# nrf7140_ml register map
Vendor: Nordic Semiconductor; Series: nRF71; File version: 1
Registers are 32-bit, read-write, reset 0x0 unless marked. A register's access mark holds for its fields unless they carry their own. Offsets are from the block's base; [hi:lo] are bit positions; lines under a group give offsets from that group; {n}, {i} and the like mark numbered series; 'fields as' and 'values as' point back to an identical list.

## AXONS (part 1 of 2) — Axon wrapper
Base 0x4A004000
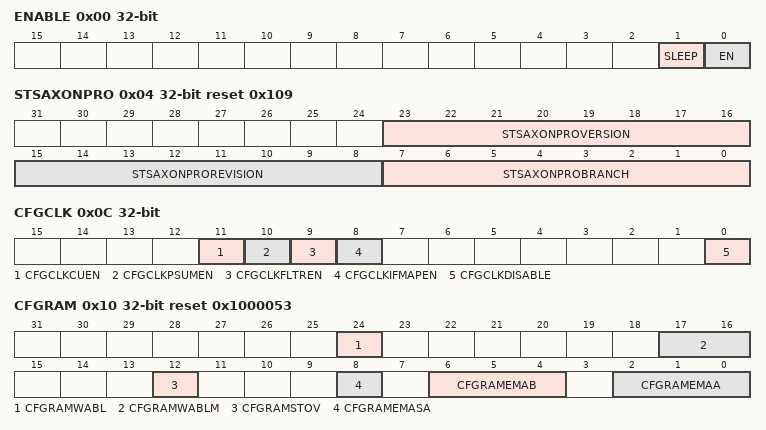
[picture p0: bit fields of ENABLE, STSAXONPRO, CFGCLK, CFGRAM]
0x00 ENABLE — Enable AXONS.
  [1] SLEEP — Enable sleep input of AXONS
    0=Disabled (AXONS sleep input not asserted.); 1=Enabled (AXONS sleep input asserted.)
  [0] EN — Enable
    0=Disabled (AXONS disabled (powered off).); 1=Enabled (AXONS enabled.)
0x800 AXONPRO group — Unspecified
  0x00 STSIP ro reset 0x2000 — ATLAZO Design ID
    [31:0] STSIPID — This is the ATLAZO IP number. It is 0x2000 to indicate Axon Pro. This can be used by FW driver to validate AXON pro location.
  0x04 STSAXONPRO ro reset 0x109 — Axon Pro Version ID
    [23:16] STSAXONPROVERSION — Axon Pro Version number. This can be used by FW driver to enable support multiple hardware versions.
    [15:8] STSAXONPROREVISION — Axon Pro Revision number
    [7:0] STSAXONPROBRANCH — Axon Pro Branch number
  0x08 CFGRESET — Soft Reset Register
    [0] CFGRESETSOFT — Active high soft reset. To perform reset, SW should write this bit to 1 then write it to 0. Doesn't reset programmable registers. Reset is performed asynchronously. Deassertion of reset is synchronized and only takes a few cycles to propagate through internal synchrnonizers
      0=NORMALOPERATION (Unspecified); 1=HOLDINRESET (Unspecified)
  0x0C CFGCLK — Clock Gating Register
    [11] CFGCLKCUEN — Active high clock enable for compute unit. Set to 0 to save power
      0=CLOCKGATEDWHENUNUSED (Unspecified); 1=CLOCKALWAYSENABLED (Unspecified)
    [10] CFGCLKPSUMEN — Active high clock enable for partial sum read DMA channel. Set to 0 to save power
      values as CFGCLKCUEN
    [9] CFGCLKFLTREN — Active high clock enable for filter read DMA channel. Set to 0 to save power
      values as CFGCLKCUEN
    [8] CFGCLKIFMAPEN — Active high clock enable for input feature map read DMA channel. Set to 0 to save power
      values as CFGCLKCUEN
    [0] CFGCLKDISABLE — Active high clock gating. Does not gate off clock to configuration registers to avoid lockup. This can be asserted when block is not in use to save power. This can also be used to measure leakage power in silicon with clocks disabled
      0=CLOCKENABLED (Unspecified); 1=CLOCKDISABLED (Unspecified)
  0x10 CFGRAM reset 0x1000053 — 22nm Ram Control Register
    [24] CFGRAMWABL — When logic 1, enable write assist for RAMs
    [17:16] CFGRAMWABLM — RAM write assist setting. 0 for 0.8V. 1 for 0.7,0.6V
    [12] CFGRAMSTOV — The RAM STOV feature allows you to override the self-timed generation of the clock pulse internal to the memory. When the STOV is asserted, the internal clock pulse is generated directly from the high phase of the external clock input.
    [8] CFGRAMEMASA — RAM EMASA enables the bitline keeper. Set EMASA to 1 to enable the bitline keeper. The memory provides a bitline keeper for Port A read operations. The keeper affects the cycle time in the read cycle. It does not affect the access time. Enabling the bitline keeper can help to counteract the effects of leakage in a high-leakage process environment.
    [6:4] CFGRAMEMAB — RAM port B pins slow down memory access and provide extra time for memory read and write operations. The access time, cycle time, and margin increase as the pins are driven from 000-111, respectively. That is, 000 is the fastest setting and 111 the slowest
    [2:0] CFGRAMEMAA — RAM port A pins slow down memory access and provide extra time for memory read and write operations. The access time, cycle time, and margin increase as the pins are driven from 000-111, respectively. That is, 000 is the fastest setting and 111 the slowest
  0x14 CFGDUMMY reset 0xC0FFEE — Dummy Register
    [31:0] CFGDUMMYVALUE — Doesn't have any associated behavior in block. Can be used by FW to test AHB slave port read and write operation
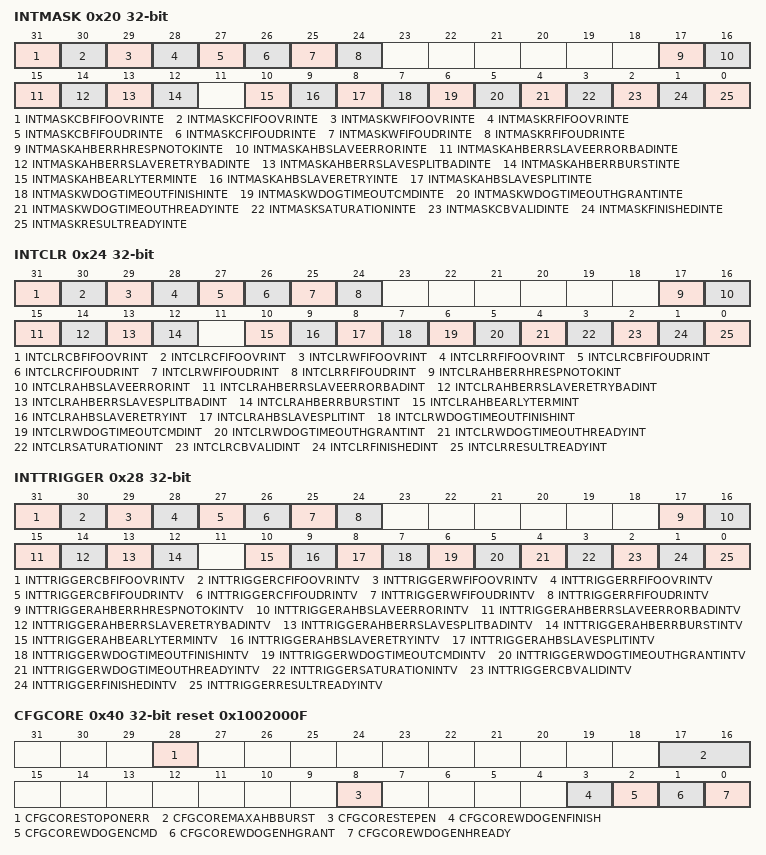
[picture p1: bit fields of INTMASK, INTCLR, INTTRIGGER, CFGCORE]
  0x20 INTMASK — Interrupt Mask Enable Register. A zero setting in any INTe bit prevents corresponding interrupt from propagating to processor.
    [all] fields
      0=INTERRUPTDISABLED (Unspecified); 1=INTERRUPTENABLED (Unspecified)
    [31] INTMASKCBFIFOOVRINTE — Enable generating Command Buffer Fifo Overun error interrupt
    [30] INTMASKCFIFOOVRINTE — Enable generating Control Fifo Overun error interrupt
    [29] INTMASKWFIFOOVRINTE — Enable generating Write data Fifo Overun error interrupt
    [28] INTMASKRFIFOOVRINTE — Enable generating Read data Fifo Overun error interrupt
    [27] INTMASKCBFIFOUDRINTE — Enable generating Command Buffer Fifo Underrun error interrupt
    [26] INTMASKCFIFOUDRINTE — Enable generating Control Fifo Underrun error interrupt
    [25] INTMASKWFIFOUDRINTE — Enable generating Write data Fifo Underrun error interrupt
    [24] INTMASKRFIFOUDRINTE — Enable generating Read data Fifo Underrun error interrupt
    [17] INTMASKAHBERRHRESPNOTOKINTE — Enable generating interrupt when following AHB behavior occurs. The slave did not follow the AHB protocol and responded with HRESP not being OKAY when expected
    [16] INTMASKAHBSLAVEERRORINTE — Enable generating interrupt when following AHB behavior occurs. The slave is indicating an error has occurred with the access
    [15] INTMASKAHBERRSLAVEERRORBADINTE — Enable generating interrupt when following AHB behavior occurs. The slave did not follow the AHB protocol when giving the HRESP ERROR
    [14] INTMASKAHBERRSLAVERETRYBADINTE — Enable generating interrupt when following AHB behavior occurs. The slave did not follow the AHB protocol when giving the HRESP RETRY
    [13] INTMASKAHBERRSLAVESPLITBADINTE — Enable generating interrupt when following AHB behavior occurs. The slave did not follow the AHB protocol when giving the HRESP SPLIT
    [12] INTMASKAHBERRBURSTINTE — Enable generating interrupt when following AHB behavior occurs. The master didn't provide the complete data for the entire burst
    [10] INTMASKAHBEARLYTERMINTE — Enable generating interrupt when AHB arbitor has terminated a burst early
    [9] INTMASKAHBSLAVERETRYINTE — Enable generating interrupt when AHB slave is telling the master to RETRY
    [8] INTMASKAHBSLAVESPLITINTE — Enable generating interrupt when AHB slave is telling the master to SPLIT
    [7] INTMASKWDOGTIMEOUTFINISHINTE — Enable generating interrupt when Axon Pro watchdog times out for processing all the command buffer
    [6] INTMASKWDOGTIMEOUTCMDINTE — Enable generating interrupt when Axon Pro watchdog times out for processing a single command
    [5] INTMASKWDOGTIMEOUTHGRANTINTE — Enable generating interrupt when Axon Pro watchdog times out for receiving hgrant on AHB master port
    [4] INTMASKWDOGTIMEOUTHREADYINTE — Enable generating interrupt when Axon Pro watchdog times out for receiving hready on AHB master port
    [3] INTMASKSATURATIONINTE — Enable generating interrupt when saturation occurs
    [2] INTMASKCBVALIDINTE — Enable generating interrupt when Axon Pro done processing valid portion of command buffer
    [1] INTMASKFINISHEDINTE — Enable generating interrupt when Axon Pro finished processing all command buffer
    [0] INTMASKRESULTREADYINTE — Enable generating interrupt when Axon Pro processed a single command and result is ready
  0x24 INTCLR — Interrupt and Clear Register. HW sets corresponding bit when interrupt event trigger occurs. FW writting any interrupt bit to 1 clears that bit.
    [all] fields
      0=NOEVENT (Unspecified); 1=EVENT (Unspecified)
    [31] INTCLRCBFIFOOVRINT — Command Buffer Fifo Overrun error Interrupt
    [30] INTCLRCFIFOOVRINT — Control Fifo Overrun error Interrupt
    [29] INTCLRWFIFOOVRINT — Write data Fifo Overrun error Interrupt
    [28] INTCLRRFIFOOVRINT — Read data Fifo Overrun error Interrupt
    [27] INTCLRCBFIFOUDRINT — Command Buffer Fifo Underrun error Interrupt
    [26] INTCLRCFIFOUDRINT — Control Fifo Underrun error Interrupt
    [25] INTCLRWFIFOUDRINT — Write Data Fifo Underrun error Interrupt
    [24] INTCLRRFIFOUDRINT — Read data Fifo Underrun error Interrupt
    [17] INTCLRAHBERRHRESPNOTOKINT — Interrupt event occures when the following AHB event occurs. The slave did not follow the AHB protocol and responded with HRESP not being OKAY when expected
    [16] INTCLRAHBSLAVEERRORINT — Interrupt event occures when the following AHB event occurs. The slave is indicating an error has occurred with the access
    [15] INTCLRAHBERRSLAVEERRORBADINT — Interrupt event occures when the following AHB event occurs. The slave did not follow the AHB protocol when giving the HRESP ERROR
    [14] INTCLRAHBERRSLAVERETRYBADINT — Interrupt event occures when the following AHB event occurs. The slave did not follow the AHB protocol when giving the HRESP RETRY
    [13] INTCLRAHBERRSLAVESPLITBADINT — Interrupt event occures when the following AHB event occurs. The slave did not follow the AHB protocol when giving the HRESP SPLIT
    [12] INTCLRAHBERRBURSTINT — Interrupt event occures when the following AHB event occurs. The master didn't provide the complete data for the entire burst
    [10] INTCLRAHBEARLYTERMINT — Interrupt event occures when the AHB arbitor has terminated a burst early
    [9] INTCLRAHBSLAVERETRYINT — Interrupt event occures when the AHB slave is telling the master to RETRY
    [8] INTCLRAHBSLAVESPLITINT — Interrupt event occures when the AHB slave is telling the master to SPLIT
    [7] INTCLRWDOGTIMEOUTFINISHINT — Interrupt event occures when all the command buffer is not processed within specified timeout limit. To recover from timeout condition, interrupt handler should 1. Disable watchdog 2. clear watchdog interrupt 3. Reset core 4. Renable watchdog
    [6] INTCLRWDOGTIMEOUTCMDINT — Interrupt event occures when a command is not processed within specified timeout limit. To recover from timeout condition, interrupt handler should 1. Disable watchdog 2. clear watchdog interrupt 3. Reset core 4. Renable watchdog
    [5] INTCLRWDOGTIMEOUTHGRANTINT — Interrupt event occures when the AHB master bus is not granted within specified timeout limit. To recover from timeout condition, interrupt handler should 1. Disable watchdog 2. clear watchdog interrupt 3. Reset core 4. Renable watchdog
    [4] INTCLRWDOGTIMEOUTHREADYINT — Interrupt event occures when AHB master bus is not ready within specified timeout limit. To recover from timeout condition, interrupt handler should 1. Disable watchdog 2. clear watchdog interrupt 3. Reset core 4. Renable watchdog
    [3] INTCLRSATURATIONINT — Interrupt event occurs when compute unit experiences saturation
    [2] INTCLRCBVALIDINT — Interrupt event occures when the Axon Pro done processing the valid portion of command buffer.
    [1] INTCLRFINISHEDINT — Interrupt event occures when the Axon Pro finishes processing all command buffer. FW needs to check all other error interrupts (result_ready_int is OK) are not asserted to determine that the command execution was successfull
    [0] INTCLRRESULTREADYINT — Interrupt event occures when the Axon Pro task is done processing one command. This is intended mainly for debug purposes
  0x28 INTTRIGGER ro — Interrupt Trigger Event. This register is not sticky and shows the trigger for the interrupt in corresponding int_clr register bit
    [31] INTTRIGGERCBFIFOOVRINTV — Command buffer Fifo Overrun error trigger
    [30] INTTRIGGERCFIFOOVRINTV — Control Fifo Overrun error trigger
    [29] INTTRIGGERWFIFOOVRINTV — Write data Fifo Overrun error trigger
    [28] INTTRIGGERRFIFOOVRINTV — Read data Fifo Overrun error trigger
    [27] INTTRIGGERCBFIFOUDRINTV — Command Buffer Fifo Underrun error trigger
    [26] INTTRIGGERCFIFOUDRINTV — Control Fifo Underrun error trigger
    [25] INTTRIGGERWFIFOUDRINTV — Write data Fifo Underrun error trigger
    [24] INTTRIGGERRFIFOUDRINTV — Read data Fifo Underrun error trigger
    [17] INTTRIGGERAHBERRHRESPNOTOKINTV — AHB Error HRESP not OK trigger
    [16] INTTRIGGERAHBSLAVEERRORINTV — AHB Slave Error trigger
    [15] INTTRIGGERAHBERRSLAVEERRORBADINTV — AHB error slave error bad trigger
    [14] INTTRIGGERAHBERRSLAVERETRYBADINTV — AHB error slave retry bad trigger
    [13] INTTRIGGERAHBERRSLAVESPLITBADINTV — AHB error slave split bad trigger
    [12] INTTRIGGERAHBERRBURSTINTV — AHB error burst trigger
    [10] INTTRIGGERAHBEARLYTERMINTV — AHB early termination trigger
    [9] INTTRIGGERAHBSLAVERETRYINTV — AHB slave retry trigger
    [8] INTTRIGGERAHBSLAVESPLITINTV — AHB slave split trigger
    [7] INTTRIGGERWDOGTIMEOUTFINISHINTV — Finished Watchdog timeout trigger
    [6] INTTRIGGERWDOGTIMEOUTCMDINTV — Command Watchdog timeout trigger
    [5] INTTRIGGERWDOGTIMEOUTHGRANTINTV — AHB master hgrant Watchdog timeout trigger
    [4] INTTRIGGERWDOGTIMEOUTHREADYINTV — AHB master hready Watchdog timeout trigger
    [3] INTTRIGGERSATURATIONINTV — Saturation trigger
    [2] INTTRIGGERCBVALIDINTV — Axon Pro done valid commad buffer trigger
    [1] INTTRIGGERFINISHEDINTV — Axon Pro Finished trigger
    [0] INTTRIGGERRESULTREADYINTV — Result ready trigger
  0x40 CFGCORE reset 0x1002000F — Configuration Register
    [28] CFGCORESTOPONERR — When 1, Axon Pro will stop when an error is detected for FW to perform a sw reset using cfg_reset_soft. When 0, Axon Pro statemachine will keep going when an error is detected
    [17:16] CFGCOREMAXAHBBURST — Specifies the maximum allowed burst size on the master AHB port
      0=SINGLE (Unspecified); 1=FOURBEATS (Unspecified); 2=EIGHTBEATS (Unspecified); 3=SIXTEENBEATS (Unspecified)
    [8] CFGCORESTEPEN — Set 1 to enable FW to step throught each command processed by triggering req_core_step. Set 0 so no FW involvement is needed per command
    [3] CFGCOREWDOGENFINISH — Set 1 to enable watchdog timer for processing all command buffer. Set 0 to disable watchdog timer
    [2] CFGCOREWDOGENCMD — Set 1 to enable watchdog timer for processing each command. Set 0 to disable watchdog timer
    [1] CFGCOREWDOGENHGRANT — Set 1 to enable watchdog timer for receiving hgrant on AHB master port. Set 0 to disable watchdog timer
    [0] CFGCOREWDOGENHREADY — Set 1 to enable watchdog timer for receiving hready on AHB master port. Set 0 to disable watchdog timer
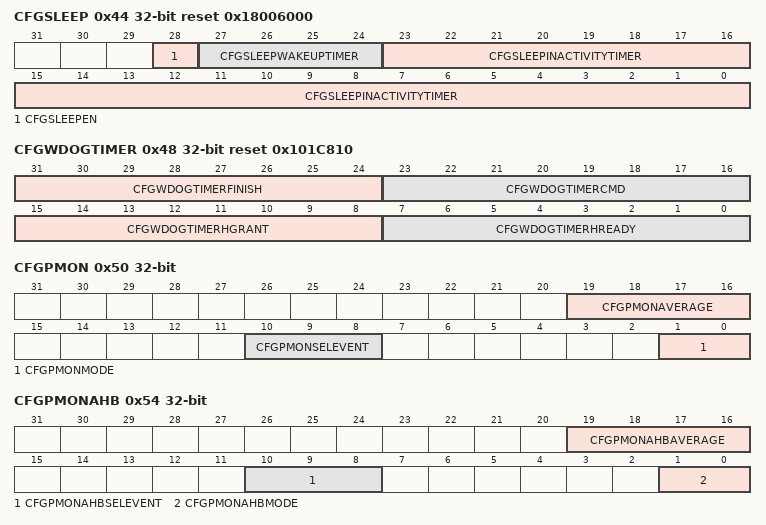
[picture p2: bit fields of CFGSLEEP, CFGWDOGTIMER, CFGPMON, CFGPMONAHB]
  0x44 CFGSLEEP reset 0x18006000 — Sleep Configuration Register
    [28] CFGSLEEPEN — When logic 1, The Axon Pro will sleep if there is no commands to process for the duraction of the time specified by cfg_sleep_inactivity_timer. The Axon Pro will automatically wakeup if any registers are written. Register reads will leave the Axon Pro in sleep. When logic 0, Axon Pro will not go into sleep mode
    [27:24] CFGSLEEPWAKEUPTIMER — Axon Pro will wait for the number of progammed cycles after wakeup to allow clock to settle
    [23:0] CFGSLEEPINACTIVITYTIMER — The number of clock cycles of inactivity to wait before going to sleep
  0x48 CFGWDOGTIMER reset 0x101C810 — Watchdog Configuration Register
    [31:24] CFGWDOGTIMERFINISH — Axon Pro will wait the programmed number of clock cyles * 2^28 for all the command buffer to finish processing, otherwise the watchdog timer will expire and trigger an interrupt
    [23:16] CFGWDOGTIMERCMD — Axon Pro will wait the programmed number of clock cyles * 2^16 for a command to finish processing, otherwise the watchdog timer will expire and trigger an interrupt
    [15:8] CFGWDOGTIMERHGRANT — Axon Pro will wait the programmed number of clock cyles to receive hgrant on AHB master port when requesting the bus, otherwise the watchdog timer will expire and trigger an interrupt
    [7:0] CFGWDOGTIMERHREADY — Axon Pro will wait the programmed number of clock cyles to receive hready on AHB master port, otherwise the watchdog timer will expire and trigger an interrupt
  0x4C CFGSPARE — Spare Register
    [31:0] CFGSPAREBIT — Spare bits, reserved for ECO. Should be set to all zero
  0x50 CFGPMON — Performance Monitor Configuration Register
    [19:16] CFGPMONAVERAGE — Amount of averaging in latency measurement mode. Value is 2 ^ cfg_pmon_average. 0 means no averaging. 1 means average two measurements. 2 means average 4 measurements. 3 means average 8 measurments, and so on
    [10:8] CFGPMONSELEVENT — In Free_Running mode, the first bit cfg_pmon_sel_event[0] = 1 means count the clock cycles only when AXON is active, 0 means keep counting. Otherwise cfg_pmon_sel_event selects which event to count or measure latency
      0=NUMINTERRUPTCYCLES (Unspecified); 1=NUMIDLECYCLES (Unspecified); 2=NUMBUSYCYCLES (Unspecified); 3=NUMFINISHEDINTERRUPTS (Unspecified); 4=NUMCOMMANDS (Unspecified); 5=NUMCONTROLBUFFERFETCHCYCLES (Unspecified); 6=NUMCOMMANDEXECUTECYCLES (Unspecified); 7=NUMFLUSHOUTPUTCYCLES (Unspecified)
    [1:0] CFGPMONMODE — Performance Monitor Mode of Operation. When disabled, sts_pmon_m/lsb_cnt is 0. When free running, sts_pmon_m/lsb_cnt is incrmenting 64 bit counter. The counter will rollover and no triggering is necessary. When counting events, the internal 64 bit counter will count the number of times the event specified by cfg_pmon_sel_event occurs. The counter will saturate when it reaches the maximum value. Once triggered by req_core_pmon_trig, sts_pmon_msb_cnt and sts_pmon_lsb_cnt will be updated with the internal counter value and the internal counter will be reset. When measuring latency, the internal 64 bit counter will start the latency measurment when triggered by req_core_pmon_trig. Once the measurement is complete, the value will be updated to sts_pmon_msb_cnt and sts_pmon_lsb_cnt and then req_core_pmon_trig will auto clear. The specific latency to measure is specifed by cfg_pmon_sel_event setting. The latency can be averaged over a number of measurments as specifed by cfg_pmon_average setting. The counter will saturate when maximum is reached
      0=DISABLED (Unspecified); 1=FREERUNNING (Unspecified); 2=EVENTCOUNT (Unspecified); 3=EVENTLATENCY (Unspecified)
  0x54 CFGPMONAHB — Performance Monitor AHB Configuration Register
    [19:16] CFGPMONAHBAVERAGE — Amount of averaging in latency measurement mode. Value is 2 ^ cfg_pmon_ahb_average. 0 means no averaging. 1 means average two measurements. 2 means average 4 measurements. 3 means average 8 measurments, and so on. After writing this bit, req_core_pmon_ahb_rw must be set 1 to take effect.
    [10:8] CFGPMONAHBSELEVENT — Select which event to count or measure latency. After writing this bit, req_core_pmon_ahb_rw must be set 1 to take effect.
      0=NUMWRITECYCLES (Unspecified); 1=NUMREADCYCLES (Unspecified); 2=NUMWRITEWAITCYCLES (Unspecified); 3=NUMREADWAITCYCLES (Unspecified); 4=NUMFIRSTREADWAITCYCLES (Unspecified); 5=NUMRESTREADWAITCYCLES (Unspecified); 6=NUMBUSCYCLES (Unspecified); 7=NUMBUSWAITCYCLES (Unspecified)
    [1:0] CFGPMONAHBMODE — Performance Monitor Mode of Operation. After writing this bit, req_core_pmon_ahb_rw must be set 1 to take effect. When disabled, sts_pmon_ahb_m/lsb_cnt is 0. When free running, sts_pmon_ahb_m/lsb_cnt is incrmenting 64 bit counter. The counter will rollover and no triggering is necessary. When counting events, the internal 64 bit counter will count the number of times the event specified by cfg_pmon_ahb_sel_event occurs. The counter will saturate when it reaches the maximum value. Once triggered by req_core_pmon_ahb_trig, sts_pmon_ahb_msb_cnt and sts_pmon_ahb_lsb_cnt will be updated with the internal counter value and the internal counter will be reset. When measuring latency, the internal 64 bit counter will start the latency measurment when triggered by req_core_pmon_ahb_trig. Once the measurement is complete, the value will be updated to sts_pmon_ahb_msb_cnt and sts_pmon_ahb_lsb_cnt and then req_core_pmon_ahb_trig will auto clear. The specific latency to measure is specifed by cfg_pmon_ahb_sel_event setting. The latency can be averaged over a number of measurments as specifed by cfg_pmon_ahb_average setting. The counter will saturate when maximum is reached
  0x7C CFGPSUMCONFIG2 — Partial Sum Configuration Register
    [15:0] CFGPSUMCONFIG2ZSTRIDE — Offset value in byte between two partial sums.
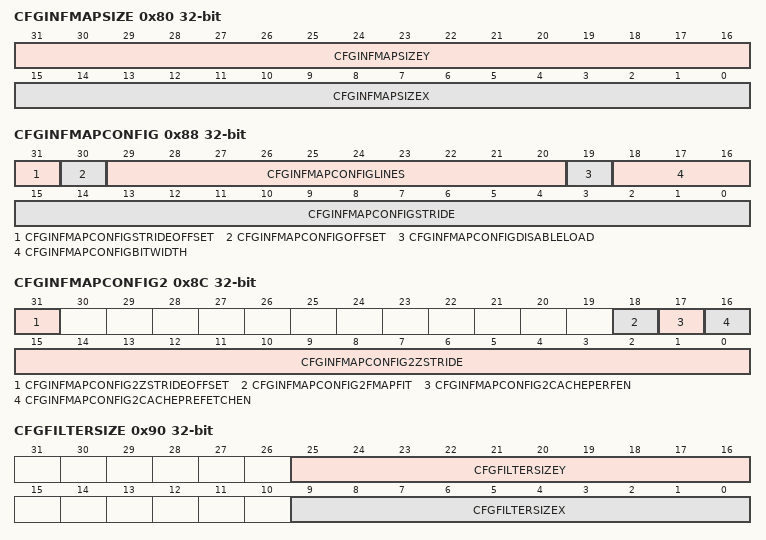
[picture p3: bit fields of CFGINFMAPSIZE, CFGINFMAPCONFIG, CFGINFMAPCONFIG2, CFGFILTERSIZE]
  0x80 CFGINFMAPSIZE — Input Feature Map Size Register
    [31:16] CFGINFMAPSIZEY — Input feature map number of rows. Units in pixels (8 bit or 4 bits)
    [15:0] CFGINFMAPSIZEX — Input feature map number of columns. Units in pixels
  0x84 CFGINFMAPPTR — Input Feature Map Pointer
    [31:0] CFGINFMAPPTRADDR — Byte address of input feature map.
  0x88 CFGINFMAPCONFIG — Input Feature Map Configuration Register
    [31] CFGINFMAPCONFIGSTRIDEOFFSET — When logic 1, addes a nibble offset to stride
    [30] CFGINFMAPCONFIGOFFSET — When logic 1, starts at upper nibble of indicated byte address in 4 bit mode. When logic 0, starts at lower nibble of indicated byte address. Must be set to 0 if bit width is larger than 4 bits.
    [29:20] CFGINFMAPCONFIGLINES — Indicates the number of lines to prefetch and use in internal line buffer storage.
    [19] CFGINFMAPCONFIGDISABLELOAD — When logic 1, AXON pro will not load input feature map from memory, instead it will reuse the previous data stored in the line buffer.
    [18:16] CFGINFMAPCONFIGBITWIDTH — Bit width of input feature map pixels. For feature map only 4 and 8 bits are supported.
      2=BITS04 (Unspecified); 3=BITS08 (Unspecified); 4=BITS16 (Unspecified); 5=BITS32 (Unspecified)
    [15:0] CFGINFMAPCONFIGSTRIDE — Offset value to required stripe of input feature map. Units in bytes. Minimum allowed value is equal to number of bytes in the columns width.
  0x8C CFGINFMAPCONFIG2 — Input Feature Map Configuration Register 2
    [31] CFGINFMAPCONFIG2ZSTRIDEOFFSET — Additional nibble offset to be added to z_stride. Used in pointwise convolution command. Should be set to0 if bit width is not 4 bit setting.
    [18] CFGINFMAPCONFIG2FMAPFIT — 1: indiacates that all fmap data fits in multi fiter modes, used for PWC and CONV only
    [17] CFGINFMAPCONFIG2CACHEPERFEN — enable fmap cache performance mode
    [16] CFGINFMAPCONFIG2CACHEPREFETCHEN — enable fmap cache prefetch mode
    [15:0] CFGINFMAPCONFIG2ZSTRIDE — Offset value in byte between two feature map surfaces.
  0x90 CFGFILTERSIZE — Filter Size Register
    [25:16] CFGFILTERSIZEY — Filter number of rows. Units in pixels
    [9:0] CFGFILTERSIZEX — Filter number of columns. Units in pixels
  0x94 CFGFILTERPTR — Filter Pointer
    [31:0] CFGFILTERPTRADDR — Byte address of filter. Must be 32 bit aligned
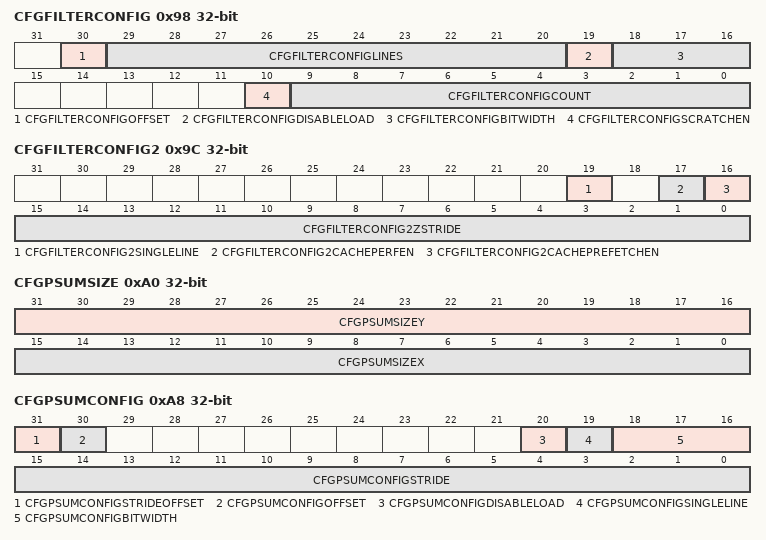
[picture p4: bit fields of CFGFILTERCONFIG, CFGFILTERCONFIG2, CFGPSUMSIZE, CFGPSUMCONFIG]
  0x98 CFGFILTERCONFIG — Filter Configuration Register
    [30] CFGFILTERCONFIGOFFSET — When logic 1, starts at upper nibble of indicated byte address in 4 bit mode. When logic 0, starts at lower nibble of indicated byte address. Must be set to 0 if bit width is larger than 4 bits.
    [29:20] CFGFILTERCONFIGLINES — Indicates the number of lines to prefetch and use in internal line buffer storage.
    [19] CFGFILTERCONFIGDISABLELOAD — When logic 1, AXON pro will not load input feature map from memory, instead it will reuse the previous data stored in the line buffer.
    [18:16] CFGFILTERCONFIGBITWIDTH — Bit width of filter pixels. For filters, only 4 bits and 8 bits supported.
      values as AXONPRO.CFGINFMAPCONFIG.CFGINFMAPCONFIGBITWIDTH
    [10] CFGFILTERCONFIGSCRATCHEN — When logic 1, filter data is stored in scratch flops to save power. This mode is limited to filters sizes upto 5x5. When logic 0, filter data is stored in internal line buffer RAM
    [9:0] CFGFILTERCONFIGCOUNT — Number of filters to apply to given input feature map
  0x9C CFGFILTERCONFIG2 — Filter Configuration Register 2
    [19] CFGFILTERCONFIG2SINGLELINE — When logic 1, all the filters are fetched using a single transaction for maximizing bus utilization. When logic 0, each filter row is fetched independantly.
    [17] CFGFILTERCONFIG2CACHEPERFEN — enable filter cache performance mode
    [16] CFGFILTERCONFIG2CACHEPREFETCHEN — enable filter cache prefetch mode
    [15:0] CFGFILTERCONFIG2ZSTRIDE — Offset value in byte between two filters surfaces. used on conv and pwc.
  0xA0 CFGPSUMSIZE — Partial Sum Size Register
    [31:16] CFGPSUMSIZEY — Partial sum number of rows. Units in pixels
    [15:0] CFGPSUMSIZEX — Partial sum number of columns. Units in rows
  0xA4 CFGPSUMPTR — Partial Sum Pointer
    [31:0] CFGPSUMPTRADDR — Byte address of partial sum. Must be 32 bit aligned
  0xA8 CFGPSUMCONFIG — Partial Sum Configuration Register
    [31] CFGPSUMCONFIGSTRIDEOFFSET — When logic 1, addes a nibble offset to stride
    [30] CFGPSUMCONFIGOFFSET — When logic 1, starts at upper nibble of indicated byte address in 4 bit mode. When logic 0, starts at lower nibble of indicated byte address. Must be set to 0 if bit width is larger than 4 bits.
    [20] CFGPSUMCONFIGDISABLELOAD — When logic 1, AXON pro will not load partial sum from memory, instead it will reuse the previous data stored in the partial sum buffer. When logic 0, AXON pro will load partial sum from memory.
    [19] CFGPSUMCONFIGSINGLELINE — When logic 1, output partial sum as a single line.
    [18:16] CFGPSUMCONFIGBITWIDTH — Bit width of partial sum pixels
      values as AXONPRO.CFGINFMAPCONFIG.CFGINFMAPCONFIGBITWIDTH
    [15:0] CFGPSUMCONFIGSTRIDE — Offset value to required stripe of partial sum. Units in bytes. Must be 32 bit aligned
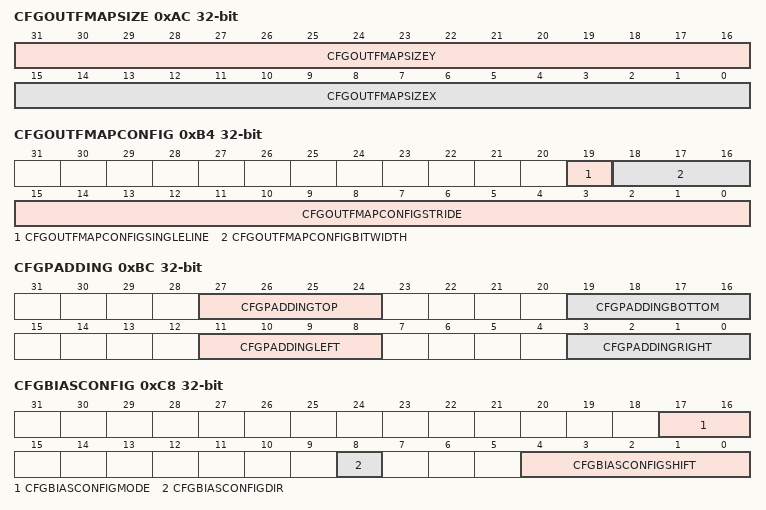
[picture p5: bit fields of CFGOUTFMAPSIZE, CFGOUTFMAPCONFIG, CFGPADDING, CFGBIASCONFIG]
  0xAC CFGOUTFMAPSIZE — Output Feature Map Size Register
    [31:16] CFGOUTFMAPSIZEY — Output feature map number of rows. Units in pixels
    [15:0] CFGOUTFMAPSIZEX — Output feature map number of columns. Units in pixels
  0xB0 CFGOUTFMAPPTR — Output Feature Map Pointer
    [31:0] CFGOUTFMAPPTRADDR — Byte address of output feature map. Must be 32 bit aligned
  0xB4 CFGOUTFMAPCONFIG — Output Feature Map Configuration Register
    [19] CFGOUTFMAPCONFIGSINGLELINE — When logic 1, output feature map as a single line
    [18:16] CFGOUTFMAPCONFIGBITWIDTH — Bit width of output feature map pixels. Only 8, 16 and 32 bits supported.
      values as AXONPRO.CFGINFMAPCONFIG.CFGINFMAPCONFIGBITWIDTH
    [15:0] CFGOUTFMAPCONFIGSTRIDE — Offset value to required stripe of output feature map. Units in bytes. Must be 32 bit aligned
  0xB8 CFGOUTFMAPCONFIG2 — Output Feature Map Config2
    [15:0] CFGOUTFMAPCONFIG2ZSTRIDE — Offset value in byte between two output feature map surfaces.
  0xBC CFGPADDING — Padding Control Register
    [27:24] CFGPADDINGTOP — Number of pixel rows to pad at top of input activation map. Units are in pixels
    [19:16] CFGPADDINGBOTTOM — Number of pixel rows to pad at bottom of input activation map. Units are in pixels
    [11:8] CFGPADDINGLEFT — Number of pixel columns to pad at left of input activation map. Units are in pixels
    [3:0] CFGPADDINGRIGHT — Number of pixel columns to pad at right of input activation map. Units are in pixels
  0xC0 CFGPADDINGCONFIG — Padding Config
    [15:0] CFGPADDINGVALUE — 16 bit signed value for padding.
  0xC4 CFGBIAS — Bias Register
    [31:0] CFGBIASVALUE — Bias value to add to output
  0xC8 CFGBIASCONFIG — Bias Configuration Register
    [17:16] CFGBIASCONFIGMODE — Where in computation pipeline to add the bias
    [8] CFGBIASCONFIGDIR — Shift direction for bias value
      0=SHIFTRIGHT (Unspecified); 1=SHIFTLEFT (Unspecified)
    [4:0] CFGBIASCONFIGSHIFT — Bias shift amount
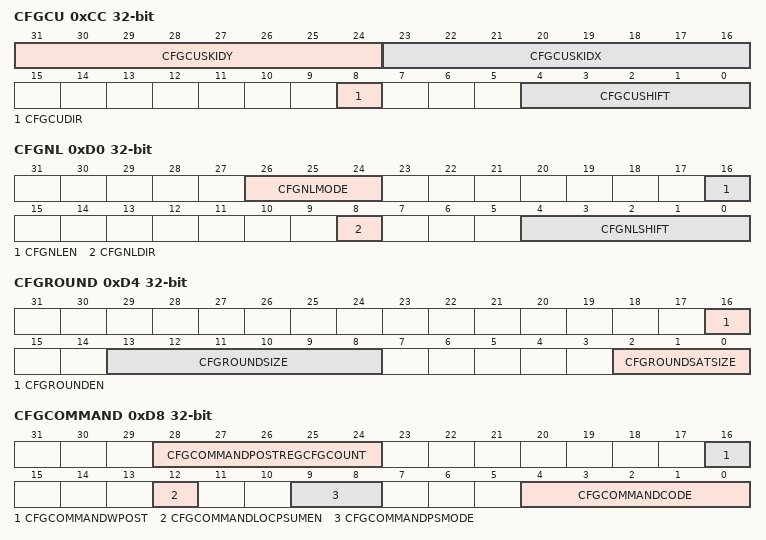
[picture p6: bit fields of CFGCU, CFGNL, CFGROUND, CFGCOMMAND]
  0xCC CFGCU — Compute Unit Configuration Register
    [31:24] CFGCUSKIDY — Number of pixel rows to move filter during convolution. Units in pixels
    [23:16] CFGCUSKIDX — Number of pixel columns to move filter during convolution. Units in pixels
    [8] CFGCUDIR — Shift direction for compute unit output
      0=SHIFTRIGHT (Unspecified); 1=SHIFTLEFT (Unspecified)
    [4:0] CFGCUSHIFT — Shift amount for compute unit output
  0xD0 CFGNL — Non Linear Configuration Register
    [26:24] CFGNLMODE — Non linear mode
      0=RELUHW (Unspecified); 1=LOOKUPTABLE16BITLSB (Unspecified); 2=LOOKUPTABLE16BITMSB (Unspecified); 3=LOOKUPTABLE32BIT (Unspecified); 5=RELULOOKUPTABLE16BITLSB (Unspecified); 6=RELULOOKUPTABLE16BITMSB (Unspecified); 7=RELULOOKUPTABLE32BIT (Unspecified)
    [16] CFGNLEN — Enable non linear
    [8] CFGNLDIR — Shift direction after non linear processing
      0=SHIFTRIGHT (Unspecified); 1=SHIFTLEFT (Unspecified)
    [4:0] CFGNLSHIFT — Shift amount after non linear processing
  0xD4 CFGROUND — Rounding and Saturation Configuration Register
    [16] CFGROUNDEN — Enable rounding
    [13:8] CFGROUNDSIZE — Rounding size
    [2:0] CFGROUNDSATSIZE — Saturation size
      values as AXONPRO.CFGINFMAPCONFIG.CFGINFMAPCONFIGBITWIDTH
  0xD8 CFGCOMMAND — Command Configurtion Register
    [28:24] CFGCOMMANDPOSTREGCFGCOUNT — number of registers that can be configured after each command. this register is only applicable to PWC and CONV with number of filters are larger than 1
    [16] CFGCOMMANDWPOST — When logic 1, writes are posted. When logic 0, writes are flushed. This should be set only if current command doesnot need output of previous command as it may still be infligt
    [12] CFGCOMMANDLOCPSUMEN — When logic 1, enable PSUM local TCM access. Setting this bit to 0 will disable access for PSUM. TCM will be used to store/read PSUM data
    [9:8] CFGCOMMANDPSMODE — Partial Sum input, output mode
      0=PARTIALNONE (Unspecified); 1=PARTIALOUT (Unspecified); 2=PARTIALIN (Unspecified); 3=PARTIALINOUT (Unspecified)
    [4:0] CFGCOMMANDCODE — Command to execute
      0=DMA (Unspecified); 1=CONV (Unspecified); 2=PWCONV (Unspecified); 3=MAXPOOL (Unspecified); 4=AVGPOOL (Unspecified); 5=MATMUL (Unspecified); 6=AXPBY (Unspecified); 7=AXPB (Unspecified); 8=XTY (Unspecified); 9=XPY (Unspecified)
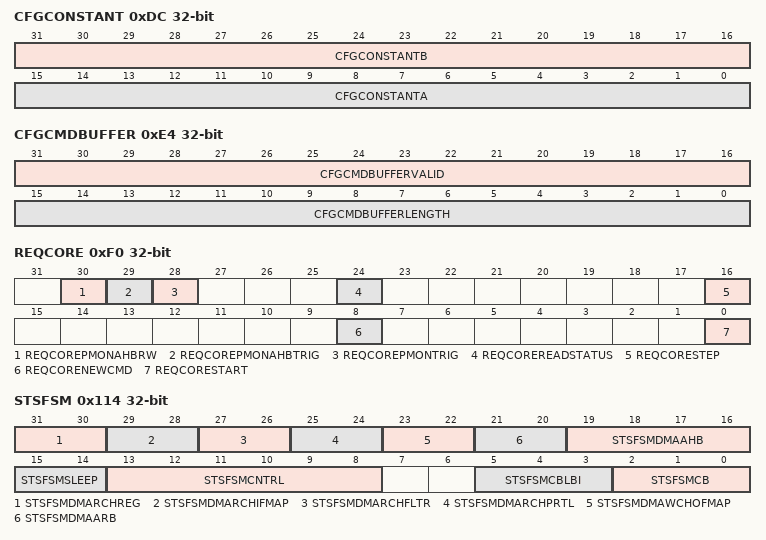
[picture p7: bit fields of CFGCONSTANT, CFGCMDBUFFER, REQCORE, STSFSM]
  0xDC CFGCONSTANT — Constant Configuration Register
    [31:16] CFGCONSTANTB — A constant value. two's complement format
    [15:0] CFGCONSTANTA — B constant value. two's complement format
  0xE0 CFGCMDBUFFERPTR — Command Buffer Pointer
    [31:0] CFGCMDBUFFERPTRADDR — Byte address of command buffer. Must be aligned to 32 bit
  0xE4 CFGCMDBUFFER — Command Buffer Configuration Register
    [31:16] CFGCMDBUFFERVALID — Number of valid DWORDS (32 bits) in command buffer. FW updates this field to synchronize with HW and let HW progress upto this location. Each Entry is atleast 64 bitss. Entry[15:0] = address. Entry[19:16] = active low write byte enable, 0 = write all 4 bytes, E=write only first byte. Entry[31:24] = number of data DWORDS. Entry[63:32] = data0, .... Little endian format, ie Entry[31:0] is lower address than Entry[63:32]
    [15:0] CFGCMDBUFFERLENGTH — Total number of DWORDS in command buffer.
  0xF0 REQCORE — Core Request Register
    [30] REQCOREPMONAHBRW — Update cfg_pmon_ahb_mode, cfg_pmon_ahb_sel_event, cfg_pmon_ahb_average settings to core.
    [29] REQCOREPMONAHBTRIG — Update sts_pmon_ahb_msb_cnt and sts_pmon_ahb_lsb_cnt. Not required in free running mode.
    [28] REQCOREPMONTRIG — Update sts_pmon_msb_cnt and sts_pmon_lsb_cnt. Not required in free running mode.
    [24] REQCOREREADSTATUS — Sample all status bits that are in the ahb clock domiain
    [16] REQCORESTEP — Proceed to executing the next command
    [8] REQCORENEWCMD — Execute new command
    [0] REQCORESTART — Start processing the command buffer
  0x100 STSCMDBUFFERPTR ro — Command Buffer Pointer Status
    [31:0] STSCMDBUFFERPTRADDR — Read back of the next byte address of commnd buffer pointer to execute. Similar to program counter in traditional processor.
  0x104 STSASLEEP ro — Sleep Status Register
    [0] STSASLEEPMODE — When logic 1, indicates Axon Pro is in sleep state. Any register write will wakeup Axon Pro
      0=NORMALMODE (Unspecified); 1=SLEEPMODE (Unspecified)
  0x108 STSMSBACC ro — Accumulator Most Significant Status Register
    [31:0] STSMSBACCRESULT — Accumulator[63:32]
  0x10C STSLSBACC ro — Accumulator Least Significant Status Register
    [31:0] STSLSBACCRESULT — Accumulator[31:0]
  0x110 STSMAHB ro — AHB Master Last Access Address Status Register
    [31:0] STSMAHBADDR — The address of the last access preformed by AHB master. Must trigger req_core_read_status to update this field
  0x114 STSFSM ro — Finite State Machines Status Register
    [31:30] STSFSMDMARCHREG — State of DMA Registers Read Channel statemachine
      0=STATEIDLE (Unspecified); 1=STATEREADREQ (Unspecified); 2=STATEREADDATA (Unspecified); 3=STATEERR (Unspecified)
    [29:28] STSFSMDMARCHIFMAP — State of DMA Input Feature Map Read Channel statemachine
      values as STSFSMDMARCHREG
    [27:26] STSFSMDMARCHFLTR — State of DMA Filter Read Channel statemachine
      values as STSFSMDMARCHREG
    [25:24] STSFSMDMARCHPRTL — State of DMA Partials Read Channel statemachine
      values as STSFSMDMARCHREG
    [23:22] STSFSMDMAWCHOFMAP — State of DMA Output Feature Map Write Channel statemachine
      0=STATEIDLE (Unspecified); 1=STATEWRITEREQ (Unspecified); 2=STATEWRITEDATA (Unspecified); 3=STATEERR (Unspecified)
    [21:20] STSFSMDMAARB — State of DMA Arbitor statemachine
      0=STATEIDLE (Unspecified); 1=STATEWRITE (Unspecified); 2=STATEREAD (Unspecified); 3=STATEERR (Unspecified)
    [19:16] STSFSMDMAAHB — State of DMA AHB interface statemachine. Must trigger req_core_read_status to update this field
      0=STATEIDLE (Unspecified); 1=STATEREQ (Unspecified); 2=STATEWRITE (Unspecified); 3=STATEREAD (Unspecified); 4=STATESWRITE (Unspecified); 5=STATESWRITEREQ (Unspecified); 6=STATESREAD (Unspecified); 7=STATESREADREQ (Unspecified); 8=STATEERR (Unspecified)
    [15:14] STSFSMSLEEP — State of sleep statemachine
      0=STATEACTIVE (Unspecified); 1=STATEINACTIVE (Unspecified); 2=STATESLEEP (Unspecified); 3=STATEWAKEUP (Unspecified)
    [13:8] STSFSMCNTRL — State of controller state machine
    [5:3] STSFSMCBLBI — State of command buffer LBI state machine
      0=STATEIDLE (Unspecified); 1=STATEADDR (Unspecified); 2=STATEDATA (Unspecified); 3=STATEWAITCMD (Unspecified); 4=STATEWAITSTEP (Unspecified)
    [2:0] STSFSMCB — State of command buffer state machine
      0=STATEIDLE (Unspecified); 1=STATESTART (Unspecified); 2=STATEREADREQ (Unspecified); 3=STATEREADDATA (Unspecified); 4=STATEWAIT (Unspecified); 5=STATEERR (Unspecified)
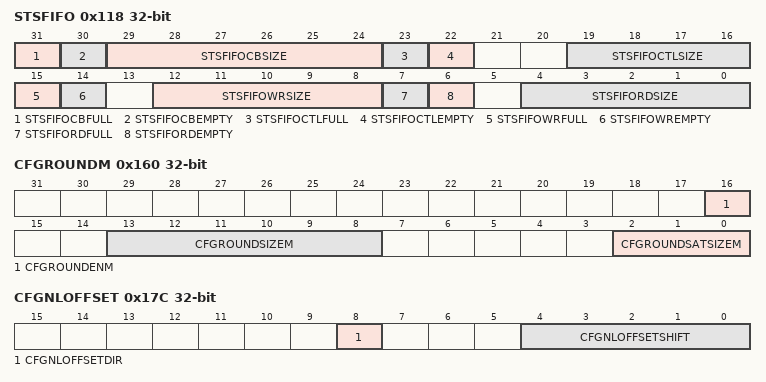
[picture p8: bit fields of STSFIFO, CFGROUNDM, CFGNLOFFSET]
  0x118 STSFIFO ro — FIFO Level Status Register
    [31] STSFIFOCBFULL — Command Buffer Fifo Full indicator
    [30] STSFIFOCBEMPTY — Command Buffer Fifo Empty indicator
    [29:24] STSFIFOCBSIZE — Number of entries used in Command Buffer Fifo
    [23] STSFIFOCTLFULL — Control Fifo Full indicator
    [22] STSFIFOCTLEMPTY — Control Fifo Empty indicator. Must trigger req_core_read_status to update this field
    [19:16] STSFIFOCTLSIZE — Number of entries used in Control Fifo
    [15] STSFIFOWRFULL — Write data Fifo Full indicator
    [14] STSFIFOWREMPTY — Write data Fifo Empty indicator. Must trigger req_core_read_status to update this field
    [12:8] STSFIFOWRSIZE — Number of entries used in Write data Fifo
    [7] STSFIFORDFULL — Read data Fifo Full indicator. Must trigger req_core_read_status to update this field
    [6] STSFIFORDEMPTY — Read data Fifo Empty indicator
    [4:0] STSFIFORDSIZE — Number of entries used in Read data Fifo
  0x11C STSDMA ro — DMA Status Register
    [7:0] STSDMACNTRFREE — The value of free entries in the read fifo
  0x120 STSPMONMSB ro — Performance Counter Most Significant Word
    [31:0] STSPMONMSBCNT — Perfromance counter bits 63 to 32. Must trigger req_core_pmon_trig to update, except in free running mode
  0x124 STSPMONLSB ro — Performance Counter Least Significant Word
    [31:0] STSPMONLSBCNT — Performance counter bits 31 to 0. Must trigger req_core_pmon_trig to update, except in free running mode
  0x128 STSPMONAHBMSB ro — Performance Counter AHB Most Significant Word
    [31:0] STSPMONAHBMSBCNT — Perfromance counter bits 63 to 32. Must trigger req_core_pmon_ahb_trig then req_core_read_status to update this field
  0x12C STSPMONAHBLSB ro — Performance Counter AHB Least Significant Word
    [31:0] STSPMONAHBLSBCNT — Performance counter bits 31 to 0. Must trigger req_core_pmon_ahb_trig then req_core_read_status to update this field
  0x160 CFGROUNDM — Rounding and Saturation Configuration Register
    [16] CFGROUNDENM — Enable rounding
    [13:8] CFGROUNDSIZEM — Rounding size
    [2:0] CFGROUNDSATSIZEM — Saturation size
      values as AXONPRO.CFGINFMAPCONFIG.CFGINFMAPCONFIGBITWIDTH
  0x164 CFGBIASM — Bias Register
    [31:0] CFGBIASVALUEM — Bias value to add to output
  0x168 CFGNLLUTM1M — Slope Register For Lookup Table Entry 1
    [31:0] CFGNLLUTM1SLOPEM — Slope value for lookup table entry 1. Input is multiplied by this slope value and added to offset. two's complement format
  0x16C CFGNLLUTO0M — Offset Register For Lookup Table Entry 0
    [31:0] CFGNLLUTO0OFFSETM — Offset value for lookup table entry 0. Used if input is less than compare point 1. Input is multiplied by slope value and added to this offset. two's complement format
  0x170 CFGNLLUTO1M — Offset Register For Lookup Table Entry 1
    [31:0] CFGNLLUTO1OFFSETM — Offset value for lookup table entry 1. Input is multiplied by slope value and added to this offset. two's complement format
  0x17C CFGNLOFFSET — Shift Registerfor Lookup Table Offset Entries
    [8] CFGNLOFFSETDIR — Shift direction for offset value in Lookup Table
      0=SHIFTRIGHT (Unspecified); 1=SHIFTLEFT (Unspecified)
    [4:0] CFGNLOFFSETSHIFT — Shift amount for offset value in Lookup Table. Should be set to number of fractional bits (q format)
  0x180 CFGNLLUTENABLE — Enable Register For Lookup Table Entries
    [8:0] CFGNLLUTENABLEEN — When 1, indicates corresponding lookup table entry is valid. When 0, indicates corresponding lookup table entry is invalid
  {0x180+4j} CFGNLLUTC{j} (j=1..8) — Compare Register For Lookup Table Entry {j}
    [31:0] CFGNLLUTC{j}COMPARE — Compare value for lookup table entry {j}. Input is compared to this value and if it matches (greater than or equal to this value and less than next entry value) the corresponding values of slope and intercept are used. two's complement format
  0x1A4 CFGNLLUTM0 — Slope Register For Lookup Table Entry 0
    [31:0] CFGNLLUTM0SLOPE — Slope value for lookup table entry 0. Used if input is less than compare point 1. Input is multiplied by this slope value and added to offset. two's complement format
  {0x1A4+4j} CFGNLLUTM{j} (j=1..8) — Slope Register For Lookup Table Entry {j}
    [31:0] CFGNLLUTM{j}SLOPE — Slope value for lookup table entry {j}. Input is multiplied by this slope value and added to offset. two's complement format
  0x1C8 CFGNLLUTO0 — Offset Register For Lookup Table Entry 0
    [31:0] CFGNLLUTO0OFFSET — Offset value for lookup table entry 0. Used if input is less than compare point 1. Input is multiplied by slope value and added to this offset. two's complement format
  {0x1C8+4j} CFGNLLUTO{j} (j=1..8) — Offset Register For Lookup Table Entry {j}
    [31:0] CFGNLLUTO{j}OFFSET — Offset value for lookup table entry {j}. Input is multiplied by slope value and added to this offset. two's complement format

## Notices in the file
Copyright (c) 2010 - 2024, Nordic Semiconductor ASA
All rights reserved.
Redistribution and use in source and binary forms, with or without modification,
are permitted provided that the following conditions are met:
1. Redistributions of source code must retain the above copyright notice, this
list of conditions and the following disclaimer.
2. Redistributions in binary form, except as embedded into a Nordic
Semiconductor ASA integrated circuit in a product or a software update for
such product, must reproduce the above copyright notice, this list of
conditions and the following disclaimer in the documentation and/or other
materials provided with the distribution.
3. Neither the name of Nordic Semiconductor ASA nor the names of its
contributors may be used to endorse or promote products derived from this
software without specific prior written permission.
4. This software, with or without modification, must only be used with a
Nordic Semiconductor ASA integrated circuit.
5. Any software provided in binary form under this license must not be reverse
engineered, decompiled, modified and/or disassembled.
THIS SOFTWARE IS PROVIDED BY NORDIC SEMICONDUCTOR ASA "AS IS" AND ANY EXPRESS
OR IMPLIED WARRANTIES, INCLUDING, BUT NOT LIMITED TO, THE IMPLIED WARRANTIES
OF MERCHANTABILITY, NONINFRINGEMENT, AND FITNESS FOR A PARTICULAR PURPOSE ARE
DISCLAIMED. IN NO EVENT SHALL NORDIC SEMICONDUCTOR ASA OR CONTRIBUTORS BE
LIABLE FOR ANY DIRECT, INDIRECT, INCIDENTAL, SPECIAL, EXEMPLARY, OR
CONSEQUENTIAL DAMAGES (INCLUDING, BUT NOT LIMITED TO, PROCUREMENT OF SUBSTITUTE
GOODS OR SERVICES; LOSS OF USE, DATA, OR PROFITS; OR BUSINESS INTERRUPTION)
HOWEVER CAUSED AND ON ANY THEORY OF LIABILITY, WHETHER IN CONTRACT, STRICT
LIABILITY, OR TORT (INCLUDING NEGLIGENCE OR OTHERWISE) ARISING IN ANY WAY OUT
OF THE USE OF THIS SOFTWARE, EVEN IF ADVISED OF THE POSSIBILITY OF SUCH DAMAGE.
